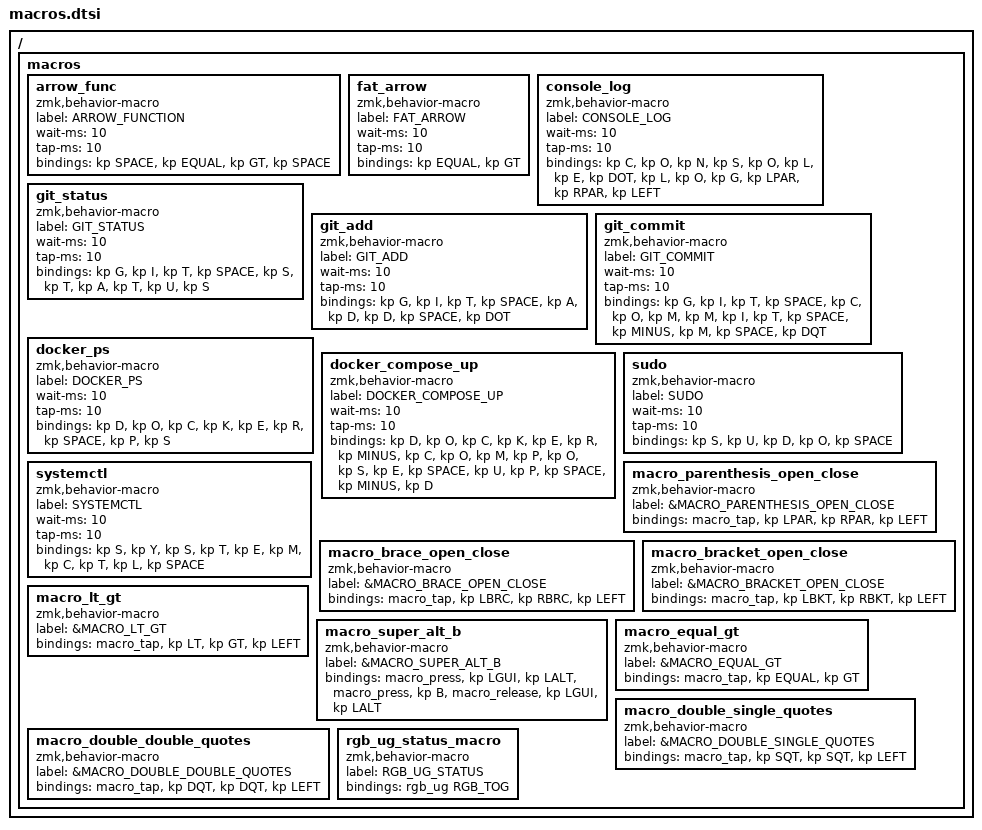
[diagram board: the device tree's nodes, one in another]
/*
 * Basic macro definitions for Glove80
 * Programming and productivity shortcuts
 */

#include <dt-bindings/zmk/rgb.h>

/ {
    macros {
        // Programming shortcuts
        arrow_func: arrow_func {
            label = "ARROW_FUNCTION";
            compatible = "zmk,behavior-macro";
            #binding-cells = <0>;
            wait-ms = <10>;
            tap-ms = <10>;
            bindings = <&kp SPACE &kp EQUAL &kp GT &kp SPACE>;
        };
        
        fat_arrow: fat_arrow {
            label = "FAT_ARROW";
            compatible = "zmk,behavior-macro";
            #binding-cells = <0>;
            wait-ms = <10>;
            tap-ms = <10>;
            bindings = <&kp EQUAL &kp GT>;
        };
        
        // Common programming patterns
        console_log: console_log {
            label = "CONSOLE_LOG";
            compatible = "zmk,behavior-macro";
            #binding-cells = <0>;
            wait-ms = <10>;
            tap-ms = <10>;
            bindings = <&kp C &kp O &kp N &kp S &kp O &kp L &kp E 
                       &kp DOT &kp L &kp O &kp G 
                       &kp LPAR &kp RPAR &kp LEFT>;
        };
        
        // Git shortcuts
        git_status: git_status {
            label = "GIT_STATUS";
            compatible = "zmk,behavior-macro";
            #binding-cells = <0>;
            wait-ms = <10>;
            tap-ms = <10>;
            bindings = <&kp G &kp I &kp T &kp SPACE 
                       &kp S &kp T &kp A &kp T &kp U &kp S>;
        };
        
        git_add: git_add {
            label = "GIT_ADD";
            compatible = "zmk,behavior-macro";
            #binding-cells = <0>;
            wait-ms = <10>;
            tap-ms = <10>;
            bindings = <&kp G &kp I &kp T &kp SPACE 
                       &kp A &kp D &kp D &kp SPACE &kp DOT>;
        };
        
        git_commit: git_commit {
            label = "GIT_COMMIT";
            compatible = "zmk,behavior-macro";
            #binding-cells = <0>;
            wait-ms = <10>;
            tap-ms = <10>;
            bindings = <&kp G &kp I &kp T &kp SPACE 
                       &kp C &kp O &kp M &kp M &kp I &kp T 
                       &kp SPACE &kp MINUS &kp M &kp SPACE &kp DQT>;
        };
        
        // Docker shortcuts
        docker_ps: docker_ps {
            label = "DOCKER_PS";
            compatible = "zmk,behavior-macro";
            #binding-cells = <0>;
            wait-ms = <10>;
            tap-ms = <10>;
            bindings = <&kp D &kp O &kp C &kp K &kp E &kp R 
                       &kp SPACE &kp P &kp S>;
        };
        
        docker_compose_up: docker_compose_up {
            label = "DOCKER_COMPOSE_UP";
            compatible = "zmk,behavior-macro";
            #binding-cells = <0>;
            wait-ms = <10>;
            tap-ms = <10>;
            bindings = <&kp D &kp O &kp C &kp K &kp E &kp R 
                       &kp MINUS &kp C &kp O &kp M &kp P &kp O &kp S &kp E 
                       &kp SPACE &kp U &kp P &kp SPACE &kp MINUS &kp D>;
        };
        
        // System shortcuts
        sudo: sudo {
            label = "SUDO";
            compatible = "zmk,behavior-macro";
            #binding-cells = <0>;
            wait-ms = <10>;
            tap-ms = <10>;
            bindings = <&kp S &kp U &kp D &kp O &kp SPACE>;
        };
        
        systemctl: systemctl {
            label = "SYSTEMCTL";
            compatible = "zmk,behavior-macro";
            #binding-cells = <0>;
            wait-ms = <10>;
            tap-ms = <10>;
            bindings = <&kp S &kp Y &kp S &kp T &kp E &kp M 
                       &kp C &kp T &kp L &kp SPACE>;
        };

        /* Auto-generated text editing macros */
        
        macro_parenthesis_open_close: macro_parenthesis_open_close {
            label = "&MACRO_PARENTHESIS_OPEN_CLOSE";
            compatible = "zmk,behavior-macro";
            #binding-cells = <0>;
            bindings = <&macro_tap>
                , <&kp LPAR>
                , <&kp RPAR>
                , <&kp LEFT>;
        };

        macro_brace_open_close: macro_brace_open_close {
            label = "&MACRO_BRACE_OPEN_CLOSE";
            compatible = "zmk,behavior-macro";
            #binding-cells = <0>;
            bindings = <&macro_tap>
                , <&kp LBRC>
                , <&kp RBRC>
                , <&kp LEFT>;
        };

        macro_bracket_open_close: macro_bracket_open_close {
            label = "&MACRO_BRACKET_OPEN_CLOSE";
            compatible = "zmk,behavior-macro";
            #binding-cells = <0>;
            bindings = <&macro_tap>
                , <&kp LBKT>
                , <&kp RBKT>
                , <&kp LEFT>;
        };

        macro_lt_gt: macro_lt_gt {
            label = "&MACRO_LT_GT";
            compatible = "zmk,behavior-macro";
            #binding-cells = <0>;
            bindings = <&macro_tap>
                , <&kp LT>
                , <&kp GT>
                , <&kp LEFT>;
        };

        macro_super_alt_b: macro_super_alt_b {
            label = "&MACRO_SUPER_ALT_B";
            compatible = "zmk,behavior-macro";
            #binding-cells = <0>;
            bindings = <&macro_press>
                , <&kp LGUI>
                , <&kp LALT>
                , <&macro_press>
                , <&kp B>
                , <&macro_release>
                , <&kp LGUI>
                , <&kp LALT>;
        };

        macro_equal_gt: macro_equal_gt {
            label = "&MACRO_EQUAL_GT";
            compatible = "zmk,behavior-macro";
            #binding-cells = <0>;
            bindings = <&macro_tap>
                , <&kp EQUAL>
                , <&kp GT>;
        };

        macro_double_single_quotes: macro_double_single_quotes {
            label = "&MACRO_DOUBLE_SINGLE_QUOTES";
            compatible = "zmk,behavior-macro";
            #binding-cells = <0>;
            bindings = <&macro_tap>
                , <&kp SQT>
                , <&kp SQT>
                , <&kp LEFT>;
        };

        macro_double_double_quotes: macro_double_double_quotes {
            label = "&MACRO_DOUBLE_DOUBLE_QUOTES";
            compatible = "zmk,behavior-macro";
            #binding-cells = <0>;
            bindings = <&macro_tap>
                , <&kp DQT>
                , <&kp DQT>
                , <&kp LEFT>;
        };

        /* RGB underglow status macro */
        rgb_ug_status_macro: rgb_ug_status_macro {
            label = "RGB_UG_STATUS";
            compatible = "zmk,behavior-macro";
            #binding-cells = <0>;
            bindings
                = <&rgb_ug RGB_TOG>;
        };
    };
};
